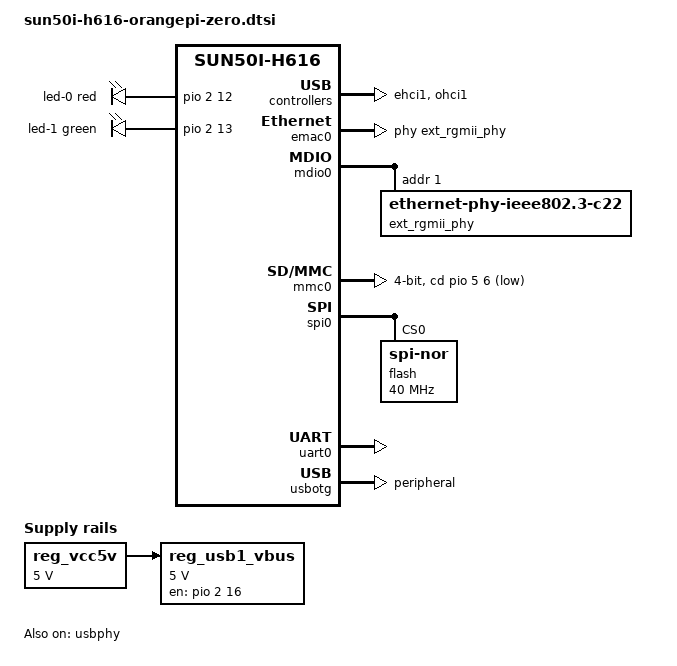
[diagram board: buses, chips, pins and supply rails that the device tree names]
#include "sun50i-h616.dtsi"
#include <dt-bindings/gpio/gpio.h>
#include <dt-bindings/interrupt-controller/arm-gic.h>
#include <dt-bindings/leds/common.h>
/ {
	aliases {
		ethernet0 = &emac0;
		serial0 = &uart0;
	};
	chosen {
		stdout-path = "serial0:115200n8";
	};
	leds {
		compatible = "gpio-leds";
		led-0 {
			function = LED_FUNCTION_POWER;
			color = <LED_COLOR_ID_RED>;
			gpios = <&pio 2 12 GPIO_ACTIVE_HIGH>;  
			default-state = "on";
		};
		led-1 {
			function = LED_FUNCTION_STATUS;
			color = <LED_COLOR_ID_GREEN>;
			gpios = <&pio 2 13 GPIO_ACTIVE_HIGH>;  
		};
	};
	reg_vcc5v: vcc5v {
		compatible = "regulator-fixed";
		regulator-name = "vcc-5v";
		regulator-min-microvolt = <5000000>;
		regulator-max-microvolt = <5000000>;
		regulator-always-on;
	};
	reg_usb1_vbus: regulator-usb1-vbus {
		compatible = "regulator-fixed";
		regulator-name = "usb1-vbus";
		regulator-min-microvolt = <5000000>;
		regulator-max-microvolt = <5000000>;
		vin-supply = <&reg_vcc5v>;
		enable-active-high;
		gpio = <&pio 2 16 GPIO_ACTIVE_HIGH>;  
	};
};
&ehci1 {
	status = "okay";
};
&emac0 {
	pinctrl-names = "default";
	pinctrl-0 = <&ext_rgmii_pins>;
	phy-handle = <&ext_rgmii_phy>;
	status = "okay";
};
&mdio0 {
	ext_rgmii_phy: ethernet-phy@1 {
		compatible = "ethernet-phy-ieee802.3-c22";
		reg = <1>;
	};
};
&mmc0 {
	cd-gpios = <&pio 5 6 GPIO_ACTIVE_LOW>;	 
	bus-width = <4>;
	status = "okay";
};
&ohci1 {
	status = "okay";
};
&spi0  {
	status = "okay";
	pinctrl-names = "default";
	pinctrl-0 = <&spi0_pins>, <&spi0_cs0_pin>;
	flash@0 {
		#address-cells = <1>;
		#size-cells = <1>;
		compatible = "jedec,spi-nor";
		reg = <0>;
		spi-max-frequency = <40000000>;
	};
};
&uart0 {
	pinctrl-names = "default";
	pinctrl-0 = <&uart0_ph_pins>;
	status = "okay";
};
&usbotg {
	dr_mode = "peripheral";
	status = "okay";
};
&usbphy {
	usb1_vbus-supply = <&reg_usb1_vbus>;
	status = "okay";
};
